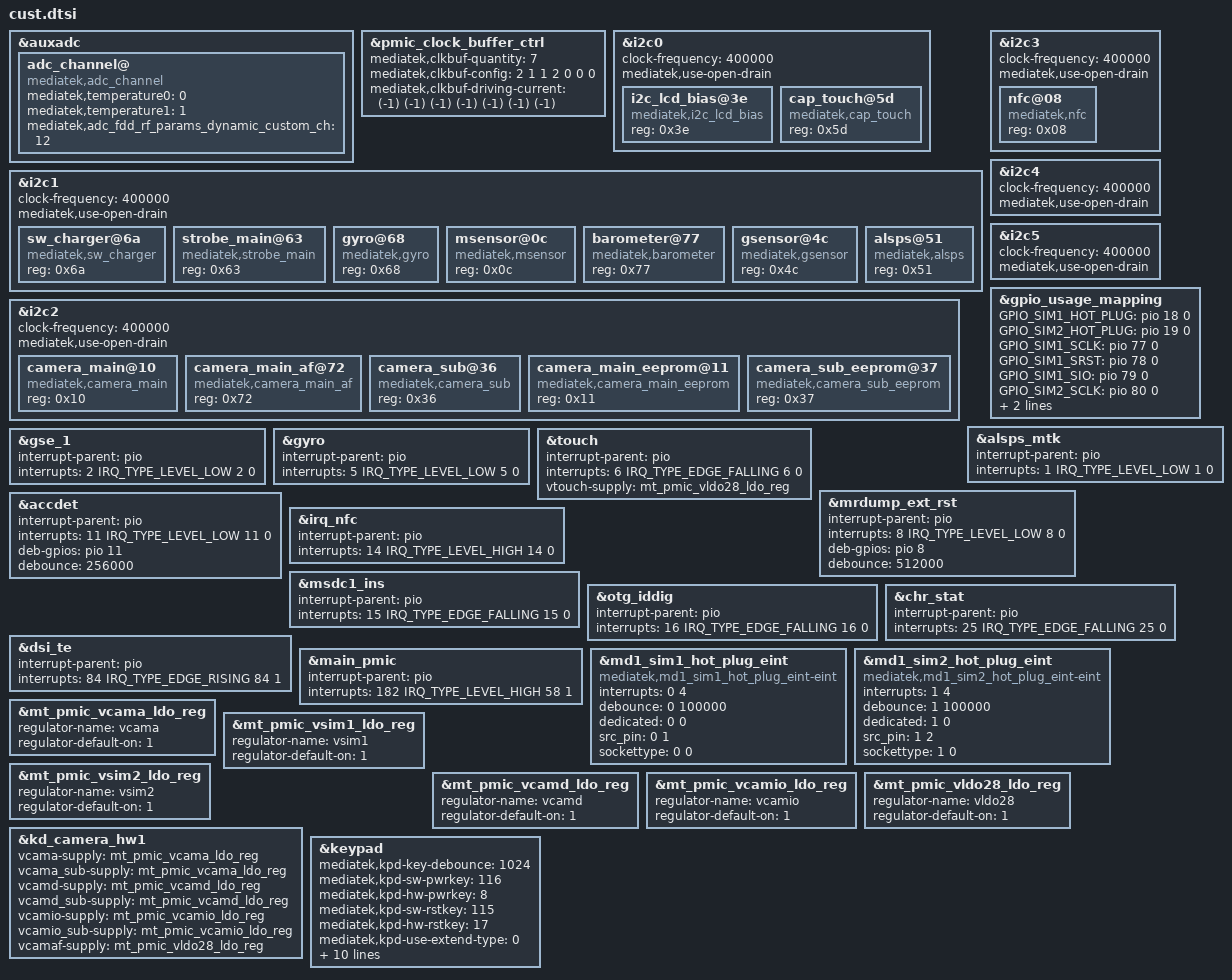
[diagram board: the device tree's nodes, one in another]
/*
 * Generated by MTK SP DrvGen Version: 3.5.160809 for MT6739.
 * 2019-11-11 10:46:44
 * Do Not Modify The File.
 * Copyright Mediatek Inc. (c) 2016.
*/

/*************************
 * ADC DTSI File
*************************/

&auxadc {
	adc_channel@ {
		compatible = "mediatek,adc_channel";
		mediatek,temperature0 = <0>;
		mediatek,temperature1 = <1>;
		mediatek,adc_fdd_rf_params_dynamic_custom_ch = <12>;
		status = "okay";
	};
};


/*************************
 * CLK_BUF DTSI File
*************************/

&pmic_clock_buffer_ctrl {
	mediatek,clkbuf-quantity = <7>;
	mediatek,clkbuf-config = <2 1 1 2 0 0 0>;
	mediatek,clkbuf-driving-current = <(-1) (-1) (-1) (-1) (-1) (-1) (-1)>;
	status = "okay";
};


/*************************
 * I2C DTSI File
*************************/

&i2c0 {
	#address-cells = <1>;
	#size-cells = <0>;
	clock-frequency = <400000>;
	mediatek,use-open-drain;
	i2c_lcd_bias@3e {
		compatible = "mediatek,i2c_lcd_bias";
		reg = <0x3e>;
		status = "okay";
	};

	cap_touch@5d {
		compatible = "mediatek,cap_touch";
		reg = <0x5d>;
		status = "okay";
	};

};

&i2c1 {
	#address-cells = <1>;
	#size-cells = <0>;
	clock-frequency = <400000>;
	mediatek,use-open-drain;
	sw_charger@6a {
		compatible = "mediatek,sw_charger";
		reg = <0x6a>;
		status = "okay";
	};

	strobe_main@63 {
		compatible = "mediatek,strobe_main";
		reg = <0x63>;
		status = "okay";
	};

	gyro@68 {
		compatible = "mediatek,gyro";
		reg = <0x68>;
		status = "okay";
	};

	msensor@0c {
		compatible = "mediatek,msensor";
		reg = <0x0c>;
		status = "okay";
	};

	barometer@77 {
		compatible = "mediatek,barometer";
		reg = <0x77>;
		status = "okay";
	};

	gsensor@4c {
		compatible = "mediatek,gsensor";
		reg = <0x4c>;
		status = "okay";
	};

	alsps@51 {
		compatible = "mediatek,alsps";
		reg = <0x51>;
		status = "okay";
	};

};

&i2c2 {
	#address-cells = <1>;
	#size-cells = <0>;
	clock-frequency = <400000>;
	mediatek,use-open-drain;
	camera_main@10 {
		compatible = "mediatek,camera_main";
		reg = <0x10>;
		status = "okay";
	};

	camera_main_af@72 {
		compatible = "mediatek,camera_main_af";
		reg = <0x72>;
		status = "okay";
	};

	camera_sub@36 {
		compatible = "mediatek,camera_sub";
		reg = <0x36>;
		status = "okay";
	};

	camera_main_eeprom@11 {
		compatible = "mediatek,camera_main_eeprom";
		reg = <0x11>;
		status = "okay";
	};

	camera_sub_eeprom@37 {
		compatible = "mediatek,camera_sub_eeprom";
		reg = <0x37>;
		status = "okay";
	};

};

&i2c3 {
	#address-cells = <1>;
	#size-cells = <0>;
	clock-frequency = <400000>;
	mediatek,use-open-drain;
	nfc@08 {
		compatible = "mediatek,nfc";
		reg = <0x08>;
		status = "okay";
	};

};

&i2c4 {
	#address-cells = <1>;
	#size-cells = <0>;
	clock-frequency = <400000>;
	mediatek,use-open-drain;
};

&i2c5 {
	#address-cells = <1>;
	#size-cells = <0>;
	clock-frequency = <400000>;
	mediatek,use-open-drain;
};



/*************************
 * GPIO DTSI File
*************************/

&gpio_usage_mapping {
	GPIO_SIM1_HOT_PLUG = <&pio 18 0>;
	GPIO_SIM2_HOT_PLUG = <&pio 19 0>;
	GPIO_SIM1_SCLK = <&pio 77 0>;
	GPIO_SIM1_SRST = <&pio 78 0>;
	GPIO_SIM1_SIO = <&pio 79 0>;
	GPIO_SIM2_SCLK = <&pio 80 0>;
	GPIO_SIM2_SRST = <&pio 81 0>;
	GPIO_SIM2_SIO = <&pio 82 0>;
};


/*************************
 * EINT DTSI File
*************************/

#include <dt-bindings/interrupt-controller/irq.h>
#include <dt-bindings/interrupt-controller/arm-gic.h>

&alsps_mtk {
	interrupt-parent = <&pio>;
	interrupts = <1 IRQ_TYPE_LEVEL_LOW 1 0>;
	status = "okay";
};

&gse_1 {
	interrupt-parent = <&pio>;
	interrupts = <2 IRQ_TYPE_LEVEL_LOW 2 0>;
	status = "okay";
};

&gyro {
	interrupt-parent = <&pio>;
	interrupts = <5 IRQ_TYPE_LEVEL_LOW 5 0>;
	status = "okay";
};

&touch {
	interrupt-parent = <&pio>;
	interrupts = <6 IRQ_TYPE_EDGE_FALLING 6 0>;
	status = "okay";
};

&mrdump_ext_rst {
	interrupt-parent = <&pio>;
	interrupts = <8 IRQ_TYPE_LEVEL_LOW 8 0>;
	deb-gpios = <&pio 8 0>;
	debounce = <512000>;
	status = "okay";
};

&accdet {
	interrupt-parent = <&pio>;
	interrupts = <11 IRQ_TYPE_LEVEL_LOW 11 0>;
	deb-gpios = <&pio 11 0>;
	debounce = <256000>;
	status = "okay";
};

&irq_nfc {
	interrupt-parent = <&pio>;
	interrupts = <14 IRQ_TYPE_LEVEL_HIGH 14 0>;
	status = "okay";
};

&msdc1_ins {
	interrupt-parent = <&pio>;
	interrupts = <15 IRQ_TYPE_EDGE_FALLING 15 0>;
	status = "okay";
};

&otg_iddig {
	interrupt-parent = <&pio>;
	interrupts = <16 IRQ_TYPE_EDGE_FALLING 16 0>;
	status = "okay";
};

&chr_stat {
	interrupt-parent = <&pio>;
	interrupts = <25 IRQ_TYPE_EDGE_FALLING 25 0>;
	status = "okay";
};

&dsi_te {
	interrupt-parent = <&pio>;
	interrupts = <84 IRQ_TYPE_EDGE_RISING 84 1>;
	status = "okay";
};

&main_pmic {
	interrupt-parent = <&pio>;
	interrupts = <182 IRQ_TYPE_LEVEL_HIGH 58 1>;
	status = "okay";
};



/*************************
 * MD1_EINT DTSI File
*************************/

&md1_sim1_hot_plug_eint {
	compatible = "mediatek,md1_sim1_hot_plug_eint-eint";
	interrupts = <0 4>;
	debounce = <0 100000>;
	dedicated = <0 0>;
	src_pin = <0 1>;
	sockettype = <0 0>;
	status = "okay";
};

&md1_sim2_hot_plug_eint {
	compatible = "mediatek,md1_sim2_hot_plug_eint-eint";
	interrupts = <1 4>;
	debounce = <1 100000>;
	dedicated = <1 0>;
	src_pin = <1 2>;
	sockettype = <1 0>;
	status = "okay";
};



/*************************
 * PMIC DTSI File
*************************/

&mt_pmic_vcama_ldo_reg {
	regulator-name = "vcama";
	regulator-default-on = <1>; /* 0:skip, 1: off, 2:on */
	status = "okay";
};
&mt_pmic_vsim1_ldo_reg {
	regulator-name = "vsim1";
	regulator-default-on = <1>; /* 0:skip, 1: off, 2:on */
	status = "okay";
};
&mt_pmic_vsim2_ldo_reg {
	regulator-name = "vsim2";
	regulator-default-on = <1>; /* 0:skip, 1: off, 2:on */
	status = "okay";
};
&mt_pmic_vcamd_ldo_reg {
	regulator-name = "vcamd";
	regulator-default-on = <1>; /* 0:skip, 1: off, 2:on */
	status = "okay";
};
&mt_pmic_vcamio_ldo_reg {
	regulator-name = "vcamio";
	regulator-default-on = <1>; /* 0:skip, 1: off, 2:on */
	status = "okay";
};
&mt_pmic_vldo28_ldo_reg {
	regulator-name = "vldo28";
	regulator-default-on = <1>; /* 0:skip, 1: off, 2:on */
	status = "okay";
};

&kd_camera_hw1 {
	vcama-supply = <&mt_pmic_vcama_ldo_reg>;
	vcama_sub-supply = <&mt_pmic_vcama_ldo_reg>;
	vcamd-supply = <&mt_pmic_vcamd_ldo_reg>;
	vcamd_sub-supply = <&mt_pmic_vcamd_ldo_reg>;
	vcamio-supply = <&mt_pmic_vcamio_ldo_reg>;
	vcamio_sub-supply = <&mt_pmic_vcamio_ldo_reg>;
	vcamaf-supply = <&mt_pmic_vldo28_ldo_reg>;
	status = "okay";
};

&touch {
	vtouch-supply = <&mt_pmic_vldo28_ldo_reg>;
	status = "okay";
};


/*************************
 * POWER DTSI File
*************************/



/*************************
 * KPD DTSI File
*************************/

&keypad {
	mediatek,kpd-key-debounce = <1024>;
	mediatek,kpd-sw-pwrkey = <116>;
	mediatek,kpd-hw-pwrkey = <8>;
	mediatek,kpd-sw-rstkey  = <115>;
	mediatek,kpd-hw-rstkey = <17>;
	mediatek,kpd-use-extend-type = <0>;
	/*HW Keycode [0~71] -> Linux Keycode*/
	mediatek,kpd-hw-map-num = <72>;
	mediatek,kpd-hw-init-map = <114 0 0 0 0 0 0 0 0 0 0 0 0 0 0 0 0 0 0 0 0 0 0 0 0 0 0 0 0 0 0 0 0 0 0 0 0 0 0 0 0 0 0 0 0 0 0 0 0 0 0 0 0 0 0 0 0 0 0 0 0 0 0 0 0 0 0 0 0 0 0 0 >;
	mediatek,kpd-pwrkey-eint-gpio = <0>;
	mediatek,kpd-pwkey-gpio-din  = <0>;
	mediatek,kpd-hw-dl-key0 = <17>;
	mediatek,kpd-hw-dl-key1 = <0>;
	mediatek,kpd-hw-dl-key2 = <8>;
	mediatek,kpd-hw-recovery-key = <17>;
	mediatek,kpd-hw-factory-key = <0>;
	status = "okay";
};


